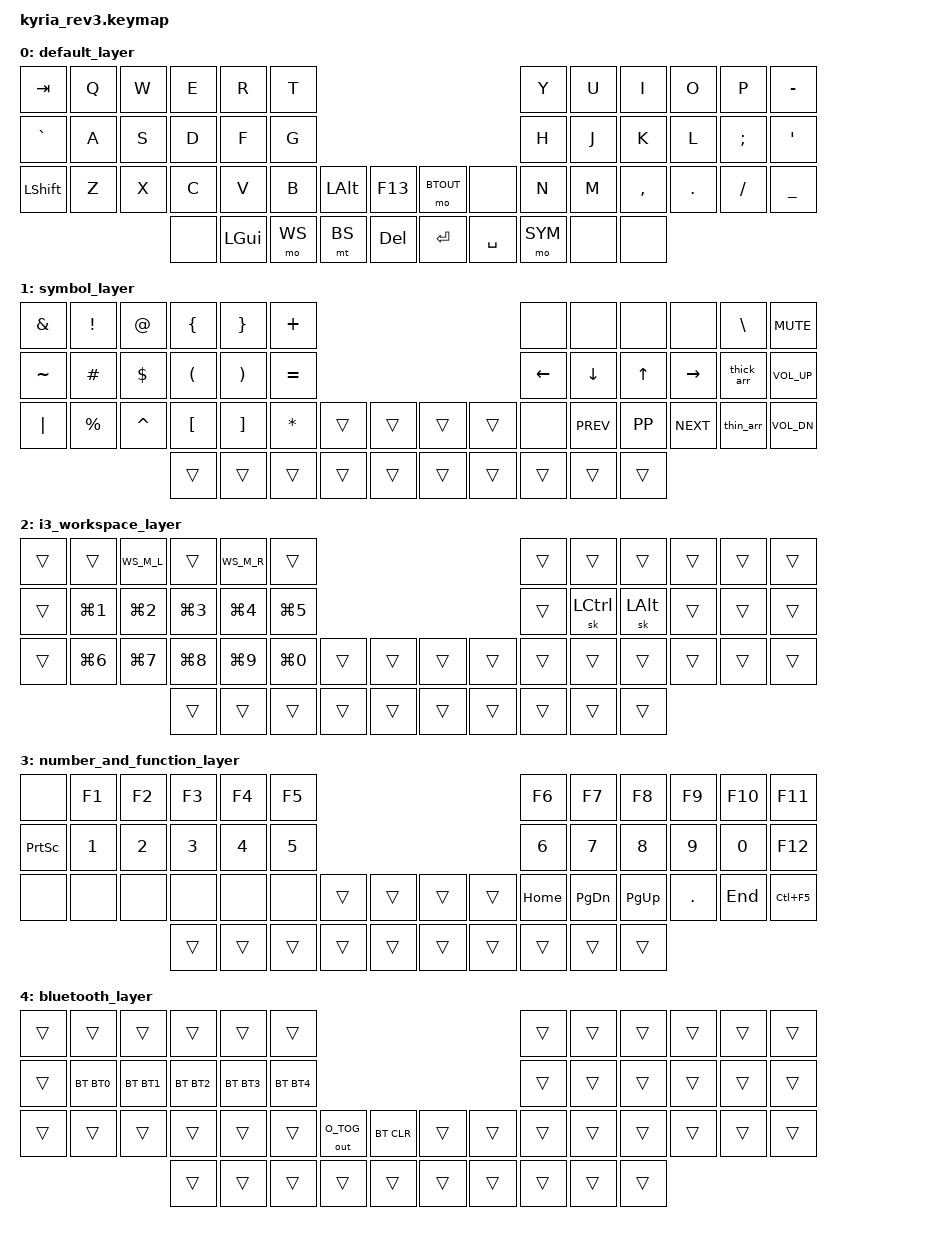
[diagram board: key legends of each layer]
#include <behaviors.dtsi>
#include <dt-bindings/zmk/bt.h>
#include <dt-bindings/zmk/keys.h>
#include <dt-bindings/zmk/outputs.h>

#define SYM 1
#define WS 2
#define NUMFN 3
#define BTOUT 4

#define C_BS LCTRL BSPC

#define WS_M_L LC(LG(LEFT))
#define WS_M_R LC(LG(RIGHT))

#define VOL_UP K_VOL_UP
#define VOL_DN K_VOL_DN

#define BT0 BT_SEL 0
#define BT1 BT_SEL 1
#define BT2 BT_SEL 2
#define BT3 BT_SEL 3
#define BT4 BT_SEL 4
#define O_TOG OUT_TOG

&mt {
    quick-tap-ms = <200>;
};

&sk {
    release-after-ms = <2000>;
};

/ {
    conditional_layers {
        compatible = "zmk,conditional-layers";
        tri_layer {
            if-layers = <SYM WS>;
            then-layer = <NUMFN>;
        };
    };

    combos {
        compatible = "zmk,combos";
        combo_esc {
            timeout-ms = <50>;
            key-positions = <19 20>; // J+K
            bindings = <&kp ESC>;
        };
    };

    macros {
        thick_arr: thick_arr {
            compatible = "zmk,behavior-macro";
            #binding-cells = <0>;
            bindings = <&macro_tap &kp EQUAL &kp GT>; // =>
        };
        thin_arr: thin_arr {
            compatible = "zmk,behavior-macro";
            #binding-cells = <0>;
            bindings = <&macro_tap &kp MINUS &kp GT>; // ->
        };
    };

    keymap {
        compatible = "zmk,keymap";

        default_layer {
            //  -----------------------------------------------------------------                                               -----------------------------------------------------------------
            // |   TAB    |    Q     |    W     |    E     |    R     |    T     |                                             |    Y     |    U     |    I     |    O     |    P     |    -     |
            // |    `     |    A     |    S     |    D     |    F     |    G     |---------------------   ---------------------|    H     |    J     |    K     |    L     |    ;     |    '     |
            // |  SHIFT   |    Z     |    X     |    C     |    V     |    B     |   ALT    |   F13    | | MO BTOUT |          |    N     |    M     |    ,     |    .     |    /     |    _     |
            //  --------------------------------|          |   MOD    |  MO WS   | BS/CTRL  |   DEL    | |  RETURN  |  SPACE   |  MO SYM  |          |          |--------------------------------
            //                                   ------------------------------------------------------   ------------------------------------------------------
            bindings = <
                &kp TAB    &kp Q      &kp W      &kp E      &kp R      &kp T                                                    &kp Y      &kp U      &kp I      &kp O      &kp P      &kp MINUS
                &kp GRAVE  &kp A      &kp S      &kp D      &kp F      &kp G                                                    &kp H      &kp J      &kp K      &kp L      &kp SEMI   &kp SQT
                &kp LSHFT  &kp Z      &kp X      &kp C      &kp V      &kp B      &kp LALT   &kp F13      &mo BTOUT  &none      &kp N      &kp M      &kp COMMA  &kp DOT    &kp FSLH   &kp UNDER
                                                 &none      &kp LGUI   &mo WS     &mt C_BS   &kp DEL      &kp RET    &kp SPACE  &mo SYM    &none      &none   
            >;
        };

        symbol_layer {
            //  -----------------------------------------------------------------                                               -----------------------------------------------------------------
            // |    &     |    !     |    @     |    {     |    }     |    +     |                                             |          |          |          |          |    \     |   MUTE   |
            // |    ~     |    #     |    $     |    (     |    )     |    =     |---------------------   ---------------------|   LEFT   |   DOWN   |    UP    |  RIGHT   |    =>    |   VOL+   |
            // |    |     |    %     |    ^     |    [     |    ]     |    *     |          |          | |          |          |          |MEDIA PREV|PLAY/PAUSE|MEDIA NEXT|    ->    |   VOL-   |
            //  --------------------------------|          |          |          |          |          | |          |          |          |          |          |--------------------------------
            //                                   ------------------------------------------------------   ------------------------------------------------------
            bindings = <
                &kp AMPS   &kp EXCL   &kp AT     &kp LBRC   &kp RBRC   &kp PLUS                                                 &none      &none      &none      &none      &kp BSLH   &kp K_MUTE
                &kp TILDE  &kp HASH   &kp DLLR   &kp LPAR   &kp RPAR   &kp EQUAL                                                &kp LEFT   &kp DOWN   &kp UP     &kp RIGHT  &thick_arr &kp VOL_UP
                &kp PIPE   &kp PRCNT  &kp CARET  &kp LBKT   &kp RBKT   &kp STAR   &trans     &trans       &trans     &trans     &none      &kp K_PREV &kp K_PP   &kp K_NEXT &thin_arr  &kp VOL_DN
                                                 &trans     &trans     &trans     &trans     &trans       &trans     &trans     &trans     &trans     &trans
            >;
        };

        i3_workspace_layer {
            //  -----------------------------------------------------------------                                               -----------------------------------------------------------------
            // |          |          |WS MOVE L |          |WS MOVE R |          |                                             |          |          |          |          |          |          |
            // |          |  MOD+1   |  MOD+2   |  MOD+3   |  MOD+4   |  MOD+5   |---------------------   ---------------------|          | CTR (OS) | ALT (OS) |          |          |          |
            // |          |  MOD+6   |  MOD+7   |  MOD+8   |  MOD+9   |  MOD+0   |          |          | |          |          |          |          |          |          |          |          |
            //  --------------------------------|          |          |          |          |          | |          |          |          |          |          |--------------------------------
            //                                   ------------------------------------------------------   ------------------------------------------------------
            bindings = <
                &trans     &trans     &kp WS_M_L &trans     &kp WS_M_R &trans                                                   &trans     &trans     &trans     &trans     &trans     &trans
                &trans     &kp LG(N1) &kp LG(N2) &kp LG(N3) &kp LG(N4) &kp LG(N5)                                               &trans     &sk LCTRL  &sk LALT   &trans     &trans     &trans
                &trans     &kp LG(N6) &kp LG(N7) &kp LG(N8) &kp LG(N9) &kp LG(N0) &trans     &trans       &trans     &trans     &trans     &trans     &trans     &trans     &trans     &trans
                                                 &trans     &trans     &trans     &trans     &trans       &trans     &trans     &trans     &trans     &trans
            >;
        };

        number_and_function_layer {
            //  -----------------------------------------------------------------                                               -----------------------------------------------------------------
            // |          |    F1    |    F2    |    F3    |    F4    |    F5    |                                             |    F6    |    F7    |    F8    |    F9    |   F10    |   F11    |
            // |  PrtScr  |    1     |    2     |    3     |    4     |    5     |---------------------   ---------------------|    6     |    7     |    8     |    9     |    0     |   F12    |
            // |          |          |          |          |          |          |          |          | |          |          |   HOME   |   PGDN   |   PGUP   |    .     |   END    |   C-F5   |
            //  --------------------------------|          |          |          |          |          | |          |          |          |          |          |--------------------------------
            //                                   ------------------------------------------------------   ------------------------------------------------------
            bindings = <
                &none      &kp F1     &kp F2     &kp F3     &kp F4     &kp F5                                                   &kp F6     &kp F7     &kp F8     &kp F9     &kp F10    &kp F11
                &kp PSCRN  &kp N1     &kp N2     &kp N3     &kp N4     &kp N5                                                   &kp N6     &kp N7     &kp N8     &kp N9     &kp N0     &kp F12
                &none      &none      &none      &none      &none      &none      &trans     &trans       &trans     &trans     &kp HOME   &kp PG_DN  &kp PG_UP  &kp DOT    &kp END    &kp LC(F5)
                                                 &trans     &trans     &trans     &trans     &trans       &trans     &trans     &trans     &trans     &trans
            >;
        };

        bluetooth_layer {
            //  -----------------------------------------------------------------                                               -----------------------------------------------------------------
            // |          |          |          |          |          |          |                                             |          |          |          |          |          |          |
            // |          |   BT0    |   BT1    |   BT2    |   BT3    |   BT4    |---------------------   ---------------------|          |          |          |          |          |          |
            // |          |          |          |          |          |          | OUT TOG  | BT CLEAR | |          |          |          |          |          |          |          |          |
            //  --------------------------------|          |          |          |          |          | |          |          |          |          |          |--------------------------------
            //                                   ------------------------------------------------------   ------------------------------------------------------
            bindings = <
                &trans     &trans     &trans     &trans     &trans     &trans                                                   &trans     &trans     &trans     &trans     &trans     &trans
                &trans     &bt BT0    &bt BT1    &bt BT2    &bt BT3    &bt BT4                                                  &trans     &trans     &trans     &trans     &trans     &trans
                &trans     &trans     &trans     &trans     &trans     &trans     &out O_TOG &bt BT_CLR   &trans     &trans     &trans     &trans     &trans     &trans     &trans     &trans
                                                 &trans     &trans     &trans     &trans     &trans       &trans     &trans     &trans     &trans     &trans
            >;
        };
    };
};
            // Blank template:
            //  -----------------------------------------------------------------                                               -----------------------------------------------------------------
            // |          |          |          |          |          |          |                                             |          |          |          |          |          |          |
            // |          |          |          |          |          |          |---------------------   ---------------------|          |          |          |          |          |          |
            // |          |          |          |          |          |          |          |          | |          |          |          |          |          |          |          |          |
            //  --------------------------------|          |          |          |          |          | |          |          |          |          |          |--------------------------------
            //                                   ------------------------------------------------------   ------------------------------------------------------
/* vim:ft=c */
